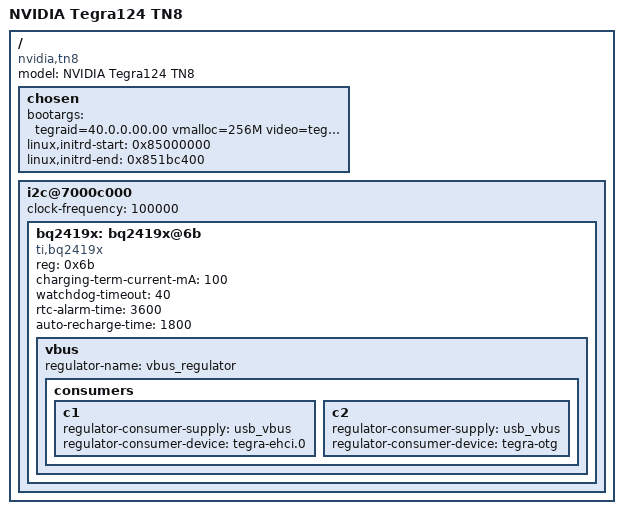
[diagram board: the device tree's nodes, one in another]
/dts-v1/;

/include/ "tegra124.dtsi"

/ {
	model = "NVIDIA Tegra124 TN8";
	compatible = "nvidia,tn8", "nvidia,tegra124";
	#address-cells = <1>;
	#size-cells = <1>;

	chosen {
		bootargs = "tegraid=40.0.0.00.00 vmalloc=256M video=tegrafb console=ttyS0,115200n8 earlyprintk";
		linux,initrd-start = <0x85000000>;
		linux,initrd-end = <0x851bc400>;
	};

	i2c@7000c000 {
		status = "okay";
		clock-frequency = <100000>;
		bq2419x: bq2419x@6b {
			compatible = "ti,bq2419x";
			reg = <0x6b>;
			charging-term-current-mA = <100>;
			watchdog-timeout = <40>;
			rtc-alarm-time = <3600>;
			auto-recharge-time = <1800>;
			vbus {
				regulator-name = "vbus_regulator";
				consumers {
					c1 {
						regulator-consumer-supply = "usb_vbus";
						regulator-consumer-device = "tegra-ehci.0";
					};

					c2 {
						regulator-consumer-supply = "usb_vbus";
						regulator-consumer-device = "tegra-otg";
					};
				};
			};
		};
	};

/include/ "tegra124-tn8b-generic.dtsi"

};

